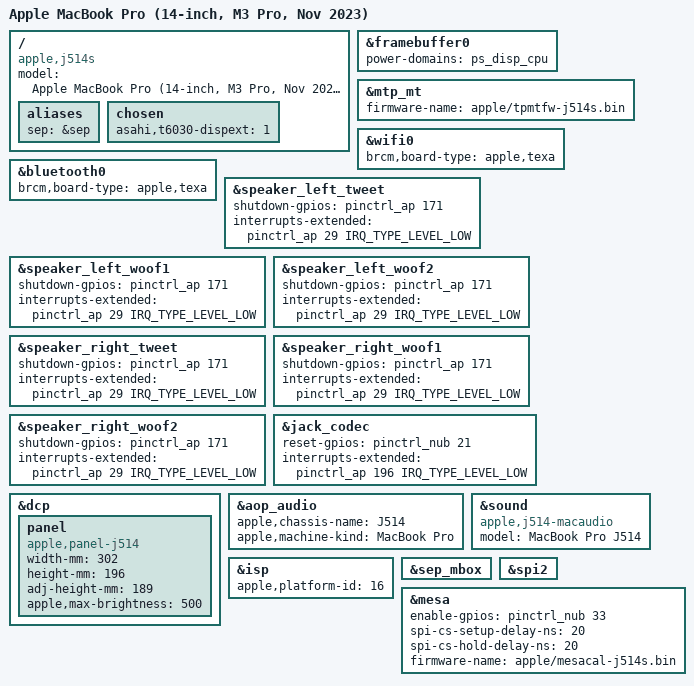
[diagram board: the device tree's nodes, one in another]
// SPDX-License-Identifier: GPL-2.0+ OR MIT
/*
 * MacBook Pro (14-inch, M3 Pro, Nov 2023)
 *
 * target-type: J514s
 *
 * Copyright The Asahi Linux Contributors
 */

/dts-v1/;

#include "t6030.dtsi"
#include "t603x-j514-j516.dtsi"
#include "t603x-j514s-j516s-usb4.dtsi"
#include "t603x-j514s-j516s-hdmi.dtsi"

/ {
	compatible = "apple,j514s", "apple,t6030", "apple,arm-platform";
	model = "Apple MacBook Pro (14-inch, M3 Pro, Nov 2023)";

	aliases {
		sep = &sep;
	};

	chosen {
		asahi,t6030-dispext = "1";
	};
};

&framebuffer0 {
	power-domains = <&ps_disp_cpu>;
};

&mtp_mt {
	firmware-name = "apple/tpmtfw-j514s.bin";
};

&wifi0 {
	brcm,board-type = "apple,texa";
};

&bluetooth0 {
	brcm,board-type = "apple,texa";
};

&speaker_left_tweet {
	shutdown-gpios = <&pinctrl_ap 171 GPIO_ACTIVE_HIGH>;
	interrupts-extended = <&pinctrl_ap 29 IRQ_TYPE_LEVEL_LOW>;
};

&speaker_left_woof1 {
	shutdown-gpios = <&pinctrl_ap 171 GPIO_ACTIVE_HIGH>;
	interrupts-extended = <&pinctrl_ap 29 IRQ_TYPE_LEVEL_LOW>;
};

&speaker_left_woof2 {
	shutdown-gpios = <&pinctrl_ap 171 GPIO_ACTIVE_HIGH>;
	interrupts-extended = <&pinctrl_ap 29 IRQ_TYPE_LEVEL_LOW>;
};

&speaker_right_tweet {
	shutdown-gpios = <&pinctrl_ap 171 GPIO_ACTIVE_HIGH>;
	interrupts-extended = <&pinctrl_ap 29 IRQ_TYPE_LEVEL_LOW>;
};

&speaker_right_woof1 {
	shutdown-gpios = <&pinctrl_ap 171 GPIO_ACTIVE_HIGH>;
	interrupts-extended = <&pinctrl_ap 29 IRQ_TYPE_LEVEL_LOW>;
};

&speaker_right_woof2 {
	shutdown-gpios = <&pinctrl_ap 171 GPIO_ACTIVE_HIGH>;
	interrupts-extended = <&pinctrl_ap 29 IRQ_TYPE_LEVEL_LOW>;
};

&jack_codec {
	reset-gpios = <&pinctrl_nub 21 GPIO_ACTIVE_HIGH>;
	interrupts-extended = <&pinctrl_ap 196 IRQ_TYPE_LEVEL_LOW>;
};

&dcp {
	panel {
		compatible = "apple,panel-j514", "apple,panel-mini-led", "apple,panel";
		width-mm = <302>;
		height-mm = <196>;
		adj-height-mm = <189>;
		apple,max-brightness = <500>;
	};
};

&aop_audio {
	apple,chassis-name = "J514";
	apple,machine-kind = "MacBook Pro";
};

&sound {
	compatible = "apple,j514-macaudio", "apple,j314-macaudio", "apple,macaudio";
	model = "MacBook Pro J514";
};

&isp {
	apple,platform-id = <16>;
};

/* apple_sep enables the SEP and its DART when it loads. */
&sep_mbox {
	status = "okay";
};

/*
 * Touch ID sensor (Mesa 0x3352, J514s ADT /arm-io/spi2/mesa): power on
 * NUB GPIO 33, active high. As on J613, the data-ready line (AP GPIO 200)
 * is left out, so the driver polls until its trigger is confirmed. Native
 * chip select only.
 */
&spi2 {
	status = "okay";
};

&mesa {
	status = "okay";
	enable-gpios = <&pinctrl_nub 33 GPIO_ACTIVE_HIGH>;
	spi-cs-setup-delay-ns = <20>;
	spi-cs-hold-delay-ns = <20>;
	/* Per-device factory data from this Mac's own iBoot system container. */
	firmware-name = "apple/mesacal-j514s.bin";
};
